# MINI1 register map
Tiny test device
CPU: CM4 r0p1, little endian
Registers are 32-bit, read-write, reset 0x0 unless marked. A register's access mark holds for its fields unless they carry their own. Offsets are from the block's base; lines under a group give offsets from that group; [hi:lo] are bit positions; {n}, {i} and the like mark numbered series; 'fields as' and 'values as' point back to an identical list; <NAME> marks a mode.

## Memory map
0x40001000 TIMER0 size 0x400 — Timer
0x40002000 TIMER1 size 0x400
0x40003000 UART size 0x100

## TIMER0 — Timer
Base 0x40001000
Same registers: TIMER1 0x40002000
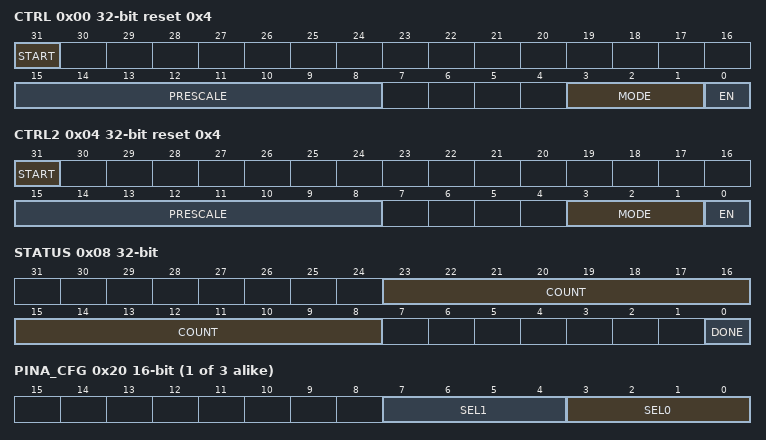
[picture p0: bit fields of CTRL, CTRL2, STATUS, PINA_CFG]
0x00 CTRL reset 0x4 — Control
  [31] START wo write-1-sets
  [15:8] PRESCALE
  [3:1] MODE
    0=OneShot (Stop at the end); 2=Periodic; 0b1x0=Capture
  [0] EN — Enable
    0=Off; 1=On
0x04 CTRL2 reset 0x4 — Control
  fields as CTRL
0x08 STATUS ro
  [23:8] COUNT
  [0] DONE
    0=Off; 1=On
0x0C DATA read-clears
{0x10+4i} CH[{i}] (i=0..3) reset 0xFFFF0000
  [15:0] VALUE
0x20 PIN{x}_CFG (x=A,B,C; step 0x2) 16-bit
  [4n+3:4n] SEL{n} (n=0..1)
{0x40+0x10*i} BUF[{i}] (i=0..1) group
  0x00 ADDR
  0x04 LEN 16-bit reset 0x10
0x60 ALT_IN
0x60 ALT_OUT (alternate view of ALT_IN)

## UART
Base 0x40003000
0x00 DR 16-bit
  [7:0] DATA read-modifies
0x04 SR 16-bit ro
  [23:8] COUNT
  [0] DONE
    0=Off; 1=On
